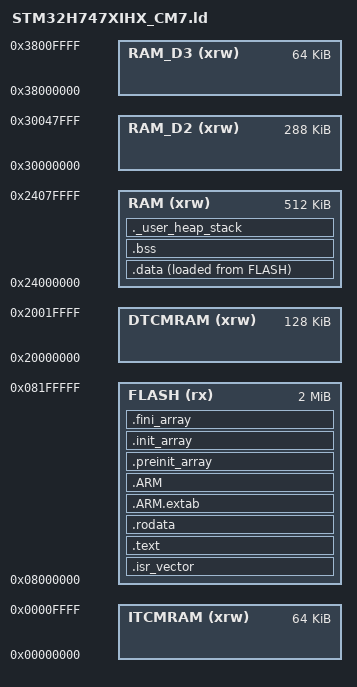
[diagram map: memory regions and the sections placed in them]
/*
 * Linker script for STM32H747XIH6 CM7 core - bare metal, no bootloader.
 * Flash starts at 0x08000000 (full 2MB for CM7).
 * Stack in DTCMRAM, code/data in AXI SRAM.
 */

ENTRY(Reset_Handler)

/* Match reference: stack at end of AXI RAM */
_estack = ORIGIN(RAM) + LENGTH(RAM);

_Min_Heap_Size  = 0x2000;
_Min_Stack_Size = 0x2000;

MEMORY
{
  FLASH    (rx)  : ORIGIN = 0x08000000, LENGTH = 2048K
  DTCMRAM  (xrw) : ORIGIN = 0x20000000, LENGTH = 128K
  RAM      (xrw) : ORIGIN = 0x24000000, LENGTH = 512K
  RAM_D2   (xrw) : ORIGIN = 0x30000000, LENGTH = 288K
  RAM_D3   (xrw) : ORIGIN = 0x38000000, LENGTH = 64K
  ITCMRAM  (xrw) : ORIGIN = 0x00000000, LENGTH = 64K
}

SECTIONS
{
  .isr_vector :
  {
    . = ALIGN(4);
    KEEP(*(.isr_vector))
    . = ALIGN(4);
  } >FLASH

  .text :
  {
    . = ALIGN(4);
    *(.text)
    *(.text*)
    *(.glue_7)
    *(.glue_7t)
    *(.eh_frame)
    KEEP(*(.init))
    KEEP(*(.fini))
    . = ALIGN(4);
    _etext = .;
  } >FLASH

  .rodata :
  {
    . = ALIGN(4);
    *(.rodata)
    *(.rodata*)
    . = ALIGN(4);
  } >FLASH

  .ARM.extab :
  {
    . = ALIGN(4);
    *(.ARM.extab* .gnu.linkonce.armextab.*)
    . = ALIGN(4);
  } >FLASH

  .ARM :
  {
    . = ALIGN(4);
    __exidx_start = .;
    *(.ARM.exidx*)
    __exidx_end = .;
    . = ALIGN(4);
  } >FLASH

  .preinit_array :
  {
    . = ALIGN(4);
    PROVIDE_HIDDEN(__preinit_array_start = .);
    KEEP(*(.preinit_array*))
    PROVIDE_HIDDEN(__preinit_array_end = .);
    . = ALIGN(4);
  } >FLASH

  .init_array :
  {
    . = ALIGN(4);
    PROVIDE_HIDDEN(__init_array_start = .);
    KEEP(*(SORT(.init_array.*)))
    KEEP(*(.init_array*))
    PROVIDE_HIDDEN(__init_array_end = .);
    . = ALIGN(4);
  } >FLASH

  .fini_array :
  {
    . = ALIGN(4);
    PROVIDE_HIDDEN(__fini_array_start = .);
    KEEP(*(SORT(.fini_array.*)))
    KEEP(*(.fini_array*))
    PROVIDE_HIDDEN(__fini_array_end = .);
    . = ALIGN(4);
  } >FLASH

  _sidata = LOADADDR(.data);

  .data :
  {
    . = ALIGN(4);
    _sdata = .;
    *(.data)
    *(.data*)
    *(.RamFunc)
    *(.RamFunc*)
    . = ALIGN(4);
    _edata = .;
  } >RAM AT> FLASH

  . = ALIGN(4);
  .bss :
  {
    _sbss = .;
    __bss_start__ = _sbss;
    *(.bss)
    *(.bss*)
    *(COMMON)
    . = ALIGN(4);
    _ebss = .;
    __bss_end__ = _ebss;
  } >RAM

  ._user_heap_stack :
  {
    . = ALIGN(8);
    PROVIDE(end = .);
    PROVIDE(_end = .);
    . = . + _Min_Heap_Size;
    . = . + _Min_Stack_Size;
    . = ALIGN(8);
  } >RAM

  /DISCARD/ :
  {
    libc.a(*)
    libm.a(*)
    libgcc.a(*)
  }

  .ARM.attributes 0 : { *(.ARM.attributes) }
}
